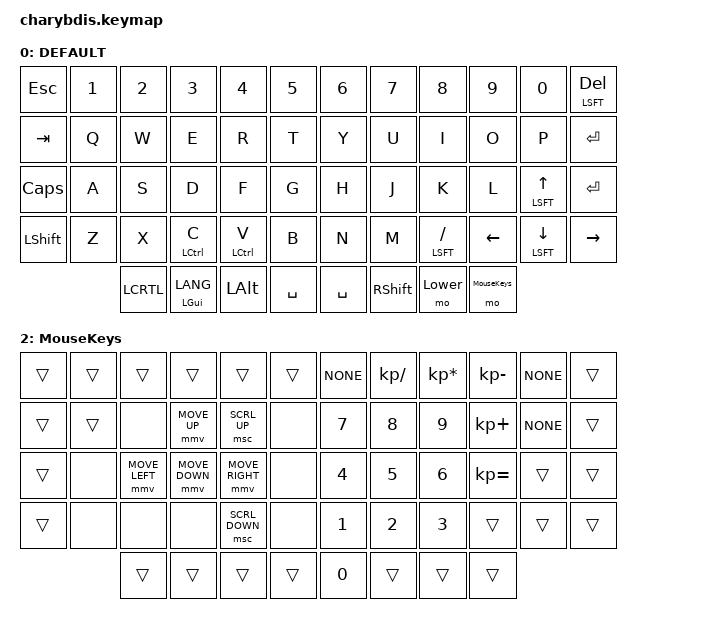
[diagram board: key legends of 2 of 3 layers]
#include <behaviors.dtsi>
#include <dt-bindings/zmk/mouse.h>
#include <dt-bindings/zmk/bt.h>
#include <dt-bindings/zmk/keys.h>
#include <dt-bindings/zmk/outputs.h>

#define DEFAULT 0
#define NUMBER  1
#define FN  2
#define HOTKEY  3



/ {
    

    combos {
        compatible = "zmk,combos";



        combo_lbrc {
            timeout-ms = <50>;
            key-positions = <4 5>; // KP: VB
            bindings = <&mt RBRC LBRC>; 
            layers = <0 1 2 3 4 5>;
        };

        combo_rbrc {
            timeout-ms = <50>;
            key-positions = <6 7>; // KP: NM
            bindings = <&kp RBRC>; 
            layers = <0 1 2 3 4 5>;
        }; 

        combo_lpar {
            timeout-ms = <50>;
            key-positions = <16 17>; // KP: FG
            bindings = <&mt RPAR LPAR>; 
            layers = <0 1 2 3 4 5>;
        };

        combo_rpar {
            timeout-ms = <50>;
            key-positions = <18 19>; 
            bindings = <&kp RPAR>; 
            layers = <0 1 2 3 4 5>;
        };

        combo_lbkt {
            timeout-ms = <50>;
            key-positions = <28 29>; // KP: RT
            bindings = <&mt RBKT LBKT>;  // 可以用CMD+这个单手返回到代码上一个编辑的地方 或者网页返回
            layers = <0 1 2 3 4 5>;
        };
        combo_rbkt {
            timeout-ms = <50>;
            key-positions = <30 31>; // KP: YU
            bindings = <&kp RBKT>; 
            layers = <0 1 2 3 4 5>;
        };

       
    };

    keymap {
        compatible = "zmk,keymap";

        default_layer {
            label = "DEFAULT";
            bindings = <
     &kp ESC                  &kp N1                    &kp N2                    &kp N3                   &kp N4                   &kp N5                    &kp N6                        &kp N7                  &kp N8                   &kp N9                 &kp N0                   &mt LSFT DELETE
// ╭────────────────────────┬────────────────────────┬────────────────────────┬────────────────────────┬────────────────────────┬────────────────────────╮    ╭────────────────────────┬────────────────────────┬────────────────────────┬───────────────────────┬────────────────────────┬────────────────────────╮
     &kp TAB                  &kp Q                    &kp W                    &kp E                    &kp R                    &kp T                         &kp Y                    &kp U                      &kp I                    &kp O                  &kp P                     &kp ENTER
// ├────────────────────────┼────────────────────────┼────────────────────────┼────────────────────────┼────────────────────────┼────────────────────────┤    ├────────────────────────┼────────────────────────┼────────────────────────┼───────────────────────┼────────────────────────┼────────────────────────┤
     &kp CAPSLOCK                &kp A                    &kp S                    &kp D                    &kp F                    &kp G                         &kp H                    &kp J                   &kp K                    &kp L                  &mt LSFT UP_ARROW         &kp ENTER
// ├────────────────────────┼────────────────────────┼────────────────────────┼────────────────────────┼────────────────────────┼────────────────────────┤    ├────────────────────────┼────────────────────────┼────────────────────────┼───────────────────────┼────────────────────────┼────────────────────────┤
     &kp LSHFT                 &kp Z                    &kp X                    &mt LCTRL C                 &mt LCTRL V              &kp B                         &kp N                    &kp M                  &mt LSFT SLASH           &kp LEFT               &mt LSFT DOWN_ARROW       &kp RIGHT
// ╰────────────────────────┴────────────────────────┴────────────────────────┴────────────────────────┼────────────────────────┼────────────────────────┤    ├────────────────────────┼────────────────────────┼────────────────────────┼───────────────────────┼────────────────────────┼────────────────────────╯
                                                          &kp LCRTL             &mt LGUI K_LANG              &kp LEFT_ALT            &kp SPACE                     &kp SPACE              &kp RSHFT                 &mo Lower                    &mo MouseKeys                        
//                                                                            ╰────────────────────────┴────────────────────────┴────────────────────────╯    ╰────────────────────────┴────────────────────────┴────────────────────────╯

      >;
        };


Lower_layer {
    display-name = "Lower";
    bindings = <
        &trans          &kp F1        &kp F2        &kp F3        &kp F4        &kp F5     &kp F6
        &kp F7          &kp F8        &kp F9        &kp F10       &trans

        &trans          &kp F11       &kp F12       &NONE         &NONE         &NONE      &kp PRINT_SCREEN
        &kp SCROLL_LOCK &kp PAUSE     &NONE         &NONE         &trans    

        &trans          &mt LSFT -    &mt LSFT =    &mt LSFT LEFT_BRACKET  &mt LSFT RIGHT_BRACKET   &mt LSFT BACKSLASH  &kp INS
        &kp HOME        &kp PGUP      &NONE         &trans        &trans        &trans

        &trans          &mt LSFT COMMA &mt LSFT DOT &mt LSFT SLASH &mt LSFT SEMI &mt LSFT SQT &kp DEL
        &kp END         &kp PGDN      &trans        &trans        &trans

        &trans          &trans        &trans        &trans        &trans        &trans
        &trans          &trans        
    >;
};


MouseKeys_layer {
      display-name = "MouseKeys";
      bindings = <
      &trans                   &trans                   &trans                   &trans                   &trans                   &trans                        &NONE                     &kp KP_SLASH            &kp KP_ASTERISK           &kp KP_MINUS             &NONE                    &trans
// ╭────────────────────────┬────────────────────────┬────────────────────────┬────────────────────────┬────────────────────────┬────────────────────────╮    ╭────────────────────────┬────────────────────────┬────────────────────────┬────────────────────────┬────────────────────────┬────────────────────────╮
      &trans                   &trans                   &none                    &mmv MOVE_UP             &msc SCRL_UP             &none                         &kp N7                    &kp N8                  &kp N9                    &kp KP_PLUS              &NONE                    &trans
// ├────────────────────────┼────────────────────────┼────────────────────────┼────────────────────────┼────────────────────────┼────────────────────────┤    ├────────────────────────┼────────────────────────┼────────────────────────┼────────────────────────┼────────────────────────┼────────────────────────┤
      &trans                   &none                    &mmv MOVE_LEFT           &mmv MOVE_DOWN           &mmv MOVE_RIGHT          &none                         &kp N4                    &kp N5                  &kp N6                    &kp KP_EQUAL             &trans                   &trans
// ├────────────────────────┼────────────────────────┼────────────────────────┼────────────────────────┼────────────────────────┼────────────────────────┤    ├────────────────────────┼────────────────────────┼────────────────────────┼────────────────────────┼────────────────────────┼────────────────────────┤
      &trans                   &none                    &none                    &none                    &msc SCRL_DOWN           &none                         &kp N1                    &kp N2                  &kp N3                    &trans                   &trans                   &trans
// ╰────────────────────────┴────────────────────────┴────────────────────────┴────────────────────────┼────────────────────────┼────────────────────────┤    ├────────────────────────┼────────────────────────┼────────────────────────┼────────────────────────┴────────────────────────┼────────────────────────╯
                                                        &trans                   &trans                   &trans                   &trans                        &kp N0                    &trans                  &trans                    &trans                 
//                                                                            ╰────────────────────────┴────────────────────────┴────────────────────────╯    ╰────────────────────────┴────────────────────────┴────────────────────────╯
      >;
    };







    };
};
